# STM32WBA25xx register map
File version: 1.0
Registers are 32-bit, read-write, reset 0x0 unless marked. A register's access mark holds for its fields unless they carry their own. Offsets are from the block's base; [hi:lo] are bit positions; {n}, {i} and the like mark numbered series.

## USB_DRD_FS — Universal Serial Bus Full Speed Dual Role Device
Base 0x40016000
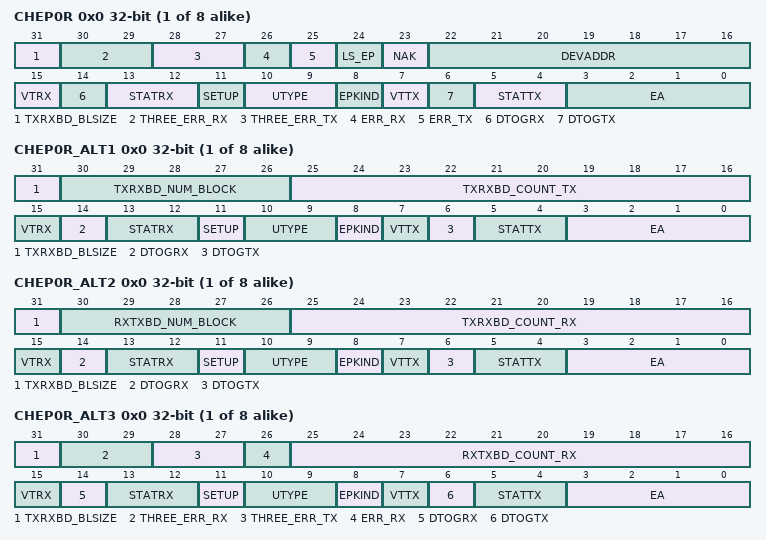
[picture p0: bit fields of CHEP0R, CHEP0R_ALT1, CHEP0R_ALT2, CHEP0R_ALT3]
{0x0+4i} CHEP{i}R (i=0..7) — USB Channel/Endpoint {i} register
  [31] TXRXBD_BLSIZE — BLSIZE (Block size)
  [30:29] THREE_ERR_RX — THREE_ERR_RX[1:0] bits (Three errors for an IN transaction)
  [28:27] THREE_ERR_TX — THREE_ERR_TX[1:0] bits (Three errors for an OUT or SETUP transaction)
  [26] ERR_RX — ERR_RX (Received error for an IN transaction)
  [25] ERR_TX — ERR_TX (Received error for an OUT/SETUP transaction)
  [24] LS_EP — LS_EP (Low speed endpoint and host with HUB only)
  [23] NAK — NAK (Host mode)
  [22:16] DEVADDR — DEVADDR[6:0] bits (Host mode)
  [15] VTRX — VTRX (USB valid transaction received)
  [14] DTOGRX — DTOGRX (Data Toggle, for reception transfers)
  [13:12] STATRX — STATRX[1:0] bits (Status bits, for reception transfers)
  [11] SETUP — SETUP (Setup transaction completed)
  [10:9] UTYPE — UTYPE[1:0] bits (USB type of transaction)
  [8] EPKIND — EPKIND (endpoint/channel kind)
  [7] VTTX — VTTX (Valid USB transaction transmitted)
  [6] DTOGTX — DTOGTX (Data toggle, for transmission transfers)
  [5:4] STATTX — STATTX[1:0] bits (Status bits, for transmission transfers)
  [3:0] EA — EA[3:0] bits (endpoint/channel address)
{0x0+4i} CHEP{i}R_ALT1 (alternate view of CHEP{i}R) (i=0..7) — USB Channel/Endpoint {i} register
  [31] TXRXBD_BLSIZE — BLSIZE (Block size)
  [30:26] TXRXBD_NUM_BLOCK — NUM_BLOCK[4:0] bits (Number of blocks)
  [25:16] TXRXBD_COUNT_TX — COUNT_TX[9:0] bits (Transmission byte count)
  [15] VTRX — VTRX (USB valid transaction received)
  [14] DTOGRX — DTOGRX (Data Toggle, for reception transfers)
  [13:12] STATRX — STATRX[1:0] bits (Status bits, for reception transfers)
  [11] SETUP — SETUP (Setup transaction completed)
  [10:9] UTYPE — UTYPE[1:0] bits (USB type of transaction)
  [8] EPKIND — EPKIND (endpoint/channel kind)
  [7] VTTX — VTTX (Valid USB transaction transmitted)
  [6] DTOGTX — DTOGTX (Data toggle, for transmission transfers)
  [5:4] STATTX — STATTX[1:0] bits (Status bits, for transmission transfers)
  [3:0] EA — EA[3:0] bits (endpoint/channel address)
{0x0+4i} CHEP{i}R_ALT2 (alternate view of CHEP{i}R) (i=0..7) — USB Channel/Endpoint {i} register
  [31] TXRXBD_BLSIZE — BLSIZE (Block size)
  [30:26] RXTXBD_NUM_BLOCK — NUM_BLOCK[4:0] bits (Number of blocks)
  [25:16] TXRXBD_COUNT_RX — COUNT_RX[9:0] bits (Reception byte count)
  [15] VTRX — VTRX (USB valid transaction received)
  [14] DTOGRX — DTOGRX (Data Toggle, for reception transfers)
  [13:12] STATRX — STATRX[1:0] bits (Status bits, for reception transfers)
  [11] SETUP — SETUP (Setup transaction completed)
  [10:9] UTYPE — UTYPE[1:0] bits (USB type of transaction)
  [8] EPKIND — EPKIND (endpoint/channel kind)
  [7] VTTX — VTTX (Valid USB transaction transmitted)
  [6] DTOGTX — DTOGTX (Data toggle, for transmission transfers)
  [5:4] STATTX — STATTX[1:0] bits (Status bits, for transmission transfers)
  [3:0] EA — EA[3:0] bits (endpoint/channel address)
{0x0+4i} CHEP{i}R_ALT3 (alternate view of CHEP{i}R) (i=0..7) — USB Channel/Endpoint {i} register
  [31] TXRXBD_BLSIZE — BLSIZE (Block size)
  [30:29] THREE_ERR_RX — THREE_ERR_RX[1:0] bits (Three errors for an IN transaction)
  [28:27] THREE_ERR_TX — THREE_ERR_TX[1:0] bits (Three errors for an OUT or SETUP transaction)
  [26] ERR_RX — ERR_RX (Received error for an IN transaction)
  [25:16] RXTXBD_COUNT_RX — COUNT_RX[9:0] bits (Reception byte count)
  [15] VTRX — VTRX (USB valid transaction received)
  [14] DTOGRX — DTOGRX (Data Toggle, for reception transfers)
  [13:12] STATRX — STATRX[1:0] bits (Status bits, for reception transfers)
  [11] SETUP — SETUP (Setup transaction completed)
  [10:9] UTYPE — UTYPE[1:0] bits (USB type of transaction)
  [8] EPKIND — EPKIND (endpoint/channel kind)
  [7] VTTX — VTTX (Valid USB transaction transmitted)
  [6] DTOGTX — DTOGTX (Data toggle, for transmission transfers)
  [5:4] STATTX — STATTX[1:0] bits (Status bits, for transmission transfers)
  [3:0] EA — EA[3:0] bits (endpoint/channel address)
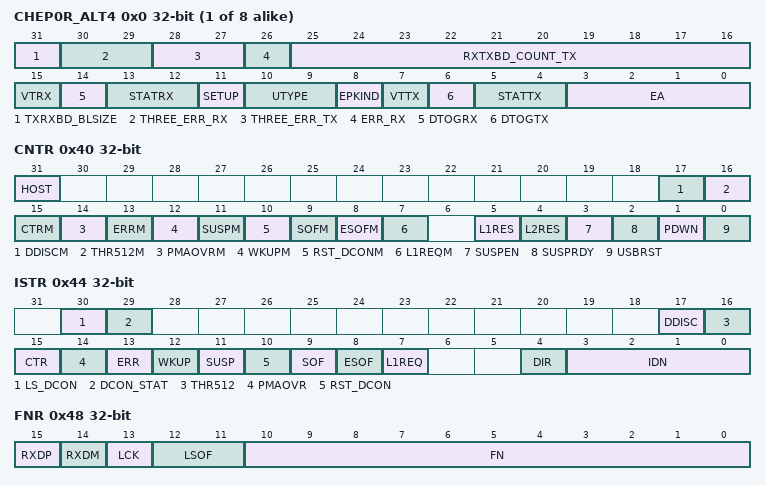
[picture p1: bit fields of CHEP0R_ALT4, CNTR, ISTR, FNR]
{0x0+4i} CHEP{i}R_ALT4 (alternate view of CHEP{i}R) (i=0..7) — USB Channel/Endpoint {i} register
  [31] TXRXBD_BLSIZE — BLSIZE (Block size)
  [30:29] THREE_ERR_RX — THREE_ERR_RX[1:0] bits (Three errors for an IN transaction)
  [28:27] THREE_ERR_TX — THREE_ERR_TX[1:0] bits (Three errors for an OUT or SETUP transaction)
  [26] ERR_RX — ERR_RX (Received error for an IN transaction)
  [25:16] RXTXBD_COUNT_TX — COUNT_TX[9:0] bits (Transmission byte count)
  [15] VTRX — VTRX (USB valid transaction received)
  [14] DTOGRX — DTOGRX (Data Toggle, for reception transfers)
  [13:12] STATRX — STATRX[1:0] bits (Status bits, for reception transfers)
  [11] SETUP — SETUP (Setup transaction completed)
  [10:9] UTYPE — UTYPE[1:0] bits (USB type of transaction)
  [8] EPKIND — EPKIND (endpoint/channel kind)
  [7] VTTX — VTTX (Valid USB transaction transmitted)
  [6] DTOGTX — DTOGTX (Data toggle, for transmission transfers)
  [5:4] STATTX — STATTX[1:0] bits (Status bits, for transmission transfers)
  [3:0] EA — EA[3:0] bits (endpoint/channel address)
0x40 CNTR — Control register
  [31] HOST — HOST (HOST mode)
  [17] DDISCM — DDISCM (Device disconnection mask)
  [16] THR512M — THR512M (512 byte threshold interrupt mask)
  [15] CTRM — CTRM (Correct transfer interrupt mask)
  [14] PMAOVRM — PMAOVRM (Packet memory area over / underrun interrupt mask)
  [13] ERRM — ERRM (Error interrupt mask)
  [12] WKUPM — WKUPM (Wake-up interrupt mask)
  [11] SUSPM — SUSPM (Suspend mode interrupt mask)
  [10] RST_DCONM — RST_DCONM (USB reset request (Device mode) or device connect/disconnect (Host mode) interrupt mask)
  [9] SOFM — SOFM (Start of frame interrupt mask)
  [8] ESOFM — ESOFM (Expected start of frame interrupt mask)
  [7] L1REQM — L1REQM (LPM L1 state request interrupt mask)
  [5] L1RES — L1RES (L1 remote wake-up / resume driver)
  [4] L2RES — L2RES (L2 remote wake-up / resume driver)
  [3] SUSPEN — SUSPEN (Suspend state enable)
  [2] SUSPRDY — SUSPRDY (Suspend state effective)
  [1] PDWN — PDWN (Power down)
  [0] USBRST — USBRST (USB Reset)
0x44 ISTR — Interrupt status register
  [30] LS_DCON — LS_DCON (Low speed device connected)
  [29] DCON_STAT — DCON_STAT (Device connection status)
  [17] DDISC — DDISC (Device connection)
  [16] THR512 — THR512 (512 byte threshold interrupt)
  [15] CTR — CTR (Completed transfer in host mode)
  [14] PMAOVR — PMAOVR (Packet memory area over / underrun)
  [13] ERR — ERR (Error)
  [12] WKUP — WKUP (Wake-up)
  [11] SUSP — SUSP (Suspend mode request)
  [10] RST_DCON — RST_DCON (USB reset request (Device mode) or device connect/disconnect (Host mode))
  [9] SOF — SOF (Start of frame)
  [8] ESOF — ESOF (Expected start of frame)
  [7] L1REQ — L1REQ (LPM L1 state request)
  [4] DIR — DIR (Direction of transaction)
  [3:0] IDN — IDN[3:0] bits (Device Endpoint / host channel identification number)
0x48 FNR — Frame number register
  [15] RXDP — RXDP (Receive data + line status)
  [14] RXDM — RXDM (Receive data - line status)
  [13] LCK — LCK (Locked)
  [12:11] LSOF — LSOF[1:0] bits (Lost SOF)
  [10:0] FN — FN[10:0] bits (Frame number)
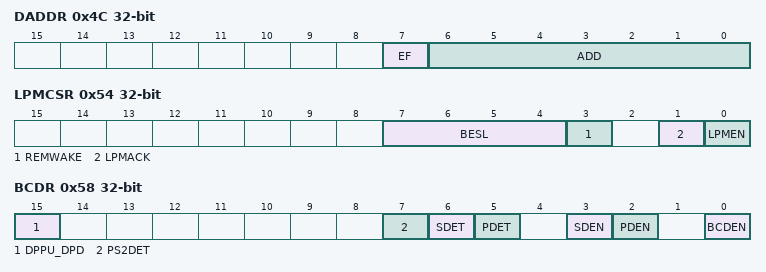
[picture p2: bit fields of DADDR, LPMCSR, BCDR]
0x4C DADDR — Device address register
  [7] EF — EF (Enable function)
  [6:0] ADD — ADD[6:0] bits (Device address)
0x54 LPMCSR — LPM Control and Status register
  [7:4] BESL — BESL[3:0] bits (BESL value)
  [3] REMWAKE — REMWAKE (bRemoteWake value)
  [1] LPMACK — LPMACK (LPM token acknowledge enable)
  [0] LPMEN — LPMEN (LPM support enable)
0x58 BCDR — Battery Charging detector register
  [15] DPPU_DPD — DPPU_DPD (DP pull-up / DPDM pull-down)
  [7] PS2DET — PS2DET (DM pull-up detection status)
  [6] SDET — SDET (Secondary detection (SD) status)
  [5] PDET — PDET (Primary detection (PD) status)
  [3] SDEN — SDEN (Secondary detection (SD) mode enable)
  [2] PDEN — PDEN (Primary detection (PD) mode enable)
  [0] BCDEN — BCDEN (Battery charging detector (BCD) enable)
